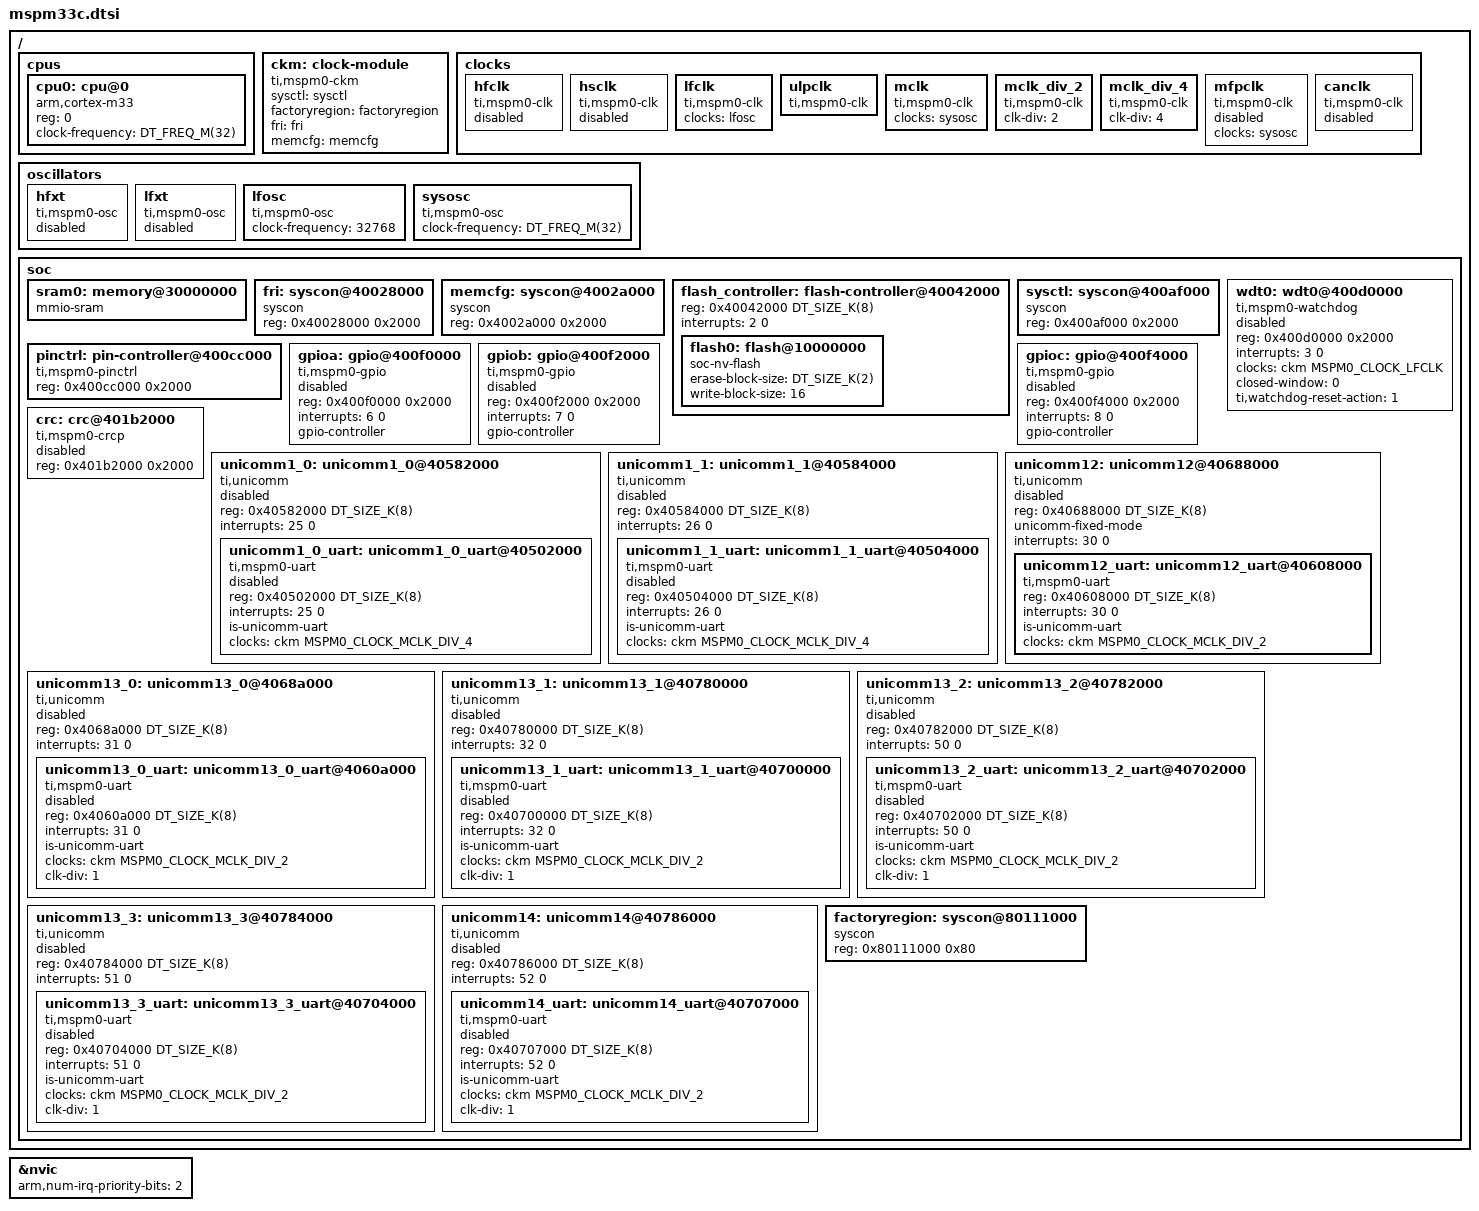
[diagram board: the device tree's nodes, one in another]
/*
 * Copyright (c) 2026 Texas Instruments
 * SPDX-License-Identifier: Apache-2.0
 */

#include <arm/armv8-m.dtsi>
#include <freq.h>
#include <zephyr/dt-bindings/clock/mspm0_clock.h>

/ {
	cpus {
		#address-cells = <1>;
		#size-cells = <0>;

		cpu0: cpu@0 {
			compatible = "arm,cortex-m33";
			reg = <0>;
			device_type = "cpu";
			clock-frequency = <DT_FREQ_M(32)>;
		};
	};

	ckm: clock-module {
		compatible = "ti,mspm0-ckm";
		#clock-cells = <1>;
		sysctl = <&sysctl>;
		factoryregion = <&factoryregion>;
		fri = <&fri>;
		memcfg = <&memcfg>;
	};

	clocks: clocks {
		hfclk: hfclk {
			compatible = "ti,mspm0-clk";
			#clock-cells = <0>;
			status = "disabled";
		};

		hsclk: hsclk {
			compatible = "ti,mspm0-clk";
			#clock-cells = <0>;
			status = "disabled";
		};

		lfclk: lfclk {
			compatible = "ti,mspm0-clk";
			#clock-cells = <0>;
			clocks = <&lfosc>;
		};

		ulpclk: ulpclk {
			compatible = "ti,mspm0-clk";
			#clock-cells = <0>;
		};

		mclk: mclk {
			compatible = "ti,mspm0-clk";
			#clock-cells = <0>;
			clocks = <&sysosc>;
		};

		mclk_div_2: mclk_div_2 {
			compatible = "ti,mspm0-clk";
			#clock-cells = <0>;
			clk-div = <2>;
		};

		mclk_div_4: mclk_div_4 {
			compatible = "ti,mspm0-clk";
			#clock-cells = <0>;
			clk-div = <4>;
		};

		mfpclk: mfpclk {
			compatible = "ti,mspm0-clk";
			#clock-cells = <0>;
			clocks = <&sysosc>;
			status = "disabled";
		};

		canclk: canclk {
			compatible = "ti,mspm0-clk";
			#clock-cells = <0>;
			status = "disabled";
		};
	};

	oscillators: oscillators {
		hfxt: hfxt {
			compatible = "ti,mspm0-osc";
			#clock-cells = <0>;
			status = "disabled";
		};

		lfxt: lfxt {
			compatible = "ti,mspm0-osc";
			#clock-cells = <0>;
			status = "disabled";
		};

		lfosc: lfosc {
			compatible = "ti,mspm0-osc";
			#clock-cells = <0>;
			clock-frequency = <32768>;
		};

		sysosc: sysosc {
			compatible = "ti,mspm0-osc";
			#clock-cells = <0>;
			clock-frequency = <DT_FREQ_M(32)>;
		};
	};

	soc {
		sram0: memory@30000000 {
			compatible = "mmio-sram";
		};

		fri: syscon@40028000 {
			compatible = "syscon";
			reg = <0x40028000 0x2000>;
		};

		memcfg: syscon@4002a000 {
			compatible = "syscon";
			reg = <0x4002a000 0x2000>;
		};

		flash_controller: flash-controller@40042000 {
			reg = <0x40042000 DT_SIZE_K(8)>;
			ranges;
			interrupts = <2 0>;
			#address-cells = <1>;
			#size-cells = <1>;

			flash0: flash@10000000 {
				compatible = "soc-nv-flash";
				erase-block-size = <DT_SIZE_K(2)>;
				write-block-size = <16>;
				#address-cells = <1>;
				#size-cells = <1>;
			};
		};

		sysctl: syscon@400af000 {
			compatible = "syscon";
			reg = <0x400af000 0x2000>;
			status = "okay";
		};

		pinctrl: pin-controller@400cc000 {
			compatible = "ti,mspm0-pinctrl";
			reg = <0x400cc000 0x2000>;
		};

		wdt0: wdt0@400d0000 {
			compatible = "ti,mspm0-watchdog";
			reg = <0x400d0000 0x2000>;
			interrupts = <3 0>;
			clocks = <&ckm MSPM0_CLOCK_LFCLK>;
			closed-window = <0>;
			ti,watchdog-reset-action = <1>;
			status = "disabled";
		};

		gpioa: gpio@400f0000 {
			compatible = "ti,mspm0-gpio";
			reg = <0x400f0000 0x2000>;
			interrupts = <6 0>;
			gpio-controller;
			#gpio-cells = <2>;
			status = "disabled";
		};

		gpiob: gpio@400f2000 {
			compatible = "ti,mspm0-gpio";
			reg = <0x400f2000 0x2000>;
			interrupts = <7 0>;
			gpio-controller;
			#gpio-cells = <2>;
			status = "disabled";
		};

		gpioc: gpio@400f4000 {
			compatible = "ti,mspm0-gpio";
			reg = <0x400f4000 0x2000>;
			interrupts = <8 0>;
			gpio-controller;
			#gpio-cells = <2>;
			status = "disabled";
		};

		crc: crc@401b2000 {
			compatible = "ti,mspm0-crcp";
			reg = <0x401b2000 0x2000>;
			status = "disabled";
		};

		unicomm1_0: unicomm1_0@40582000 {
			compatible = "ti,unicomm";
			reg = <0x40582000 DT_SIZE_K(8)>;
			interrupts = <25 0>;
			#address-cells = <1>;
			#size-cells = <1>;
			status = "disabled";

			unicomm1_0_uart: unicomm1_0_uart@40502000 {
				compatible = "ti,mspm0-uart";
				reg = <0x40502000 DT_SIZE_K(8)>;
				interrupts = <25 0>;
				#address-cells = <1>;
				#size-cells = <1>;
				is-unicomm-uart;
				clocks = <&ckm MSPM0_CLOCK_MCLK_DIV_4>;
				status = "disabled";
			};
		};

		unicomm1_1: unicomm1_1@40584000 {
			compatible = "ti,unicomm";
			reg = <0x40584000 DT_SIZE_K(8)>;
			interrupts = <26 0>;
			#address-cells = <1>;
			#size-cells = <1>;
			status = "disabled";

			unicomm1_1_uart: unicomm1_1_uart@40504000 {
				compatible = "ti,mspm0-uart";
				reg = <0x40504000 DT_SIZE_K(8)>;
				interrupts = <26 0>;
				#address-cells = <1>;
				#size-cells = <1>;
				is-unicomm-uart;
				clocks = <&ckm MSPM0_CLOCK_MCLK_DIV_4>;
				status = "disabled";
			};
		};

		unicomm12: unicomm12@40688000 {
			compatible = "ti,unicomm";
			reg = <0x40688000 DT_SIZE_K(8)>;
			unicomm-fixed-mode;
			interrupts = <30 0>;
			#address-cells = <1>;
			#size-cells = <1>;
			status = "disabled";

			unicomm12_uart: unicomm12_uart@40608000 {
				compatible = "ti,mspm0-uart";
				reg = <0x40608000 DT_SIZE_K(8)>;
				interrupts = <30 0>;
				#address-cells = <1>;
				#size-cells = <1>;
				is-unicomm-uart;
				clocks = <&ckm MSPM0_CLOCK_MCLK_DIV_2>;
			};
		};

		unicomm13_0: unicomm13_0@4068a000 {
			compatible = "ti,unicomm";
			reg = <0x4068a000 DT_SIZE_K(8)>;
			interrupts = <31 0>;
			#address-cells = <1>;
			#size-cells = <1>;
			status = "disabled";

			unicomm13_0_uart: unicomm13_0_uart@4060a000 {
				compatible = "ti,mspm0-uart";
				reg = <0x4060a000 DT_SIZE_K(8)>;
				interrupts = <31 0>;
				#address-cells = <1>;
				#size-cells = <1>;
				is-unicomm-uart;
				clocks = <&ckm MSPM0_CLOCK_MCLK_DIV_2>;
				clk-div = <1>;
				status = "disabled";
			};
		};

		unicomm13_1: unicomm13_1@40780000 {
			compatible = "ti,unicomm";
			reg = <0x40780000 DT_SIZE_K(8)>;
			interrupts = <32 0>;
			#address-cells = <1>;
			#size-cells = <1>;
			status = "disabled";

			unicomm13_1_uart: unicomm13_1_uart@40700000 {
				compatible = "ti,mspm0-uart";
				reg = <0x40700000 DT_SIZE_K(8)>;
				interrupts = <32 0>;
				#address-cells = <1>;
				#size-cells = <1>;
				is-unicomm-uart;
				clocks = <&ckm MSPM0_CLOCK_MCLK_DIV_2>;
				clk-div = <1>;
				status = "disabled";
			};
		};

		unicomm13_2: unicomm13_2@40782000 {
			compatible = "ti,unicomm";
			reg = <0x40782000 DT_SIZE_K(8)>;
			interrupts = <50 0>;
			#address-cells = <1>;
			#size-cells = <1>;
			status = "disabled";

			unicomm13_2_uart: unicomm13_2_uart@40702000 {
				compatible = "ti,mspm0-uart";
				reg = <0x40702000 DT_SIZE_K(8)>;
				interrupts = <50 0>;
				#address-cells = <1>;
				#size-cells = <1>;
				is-unicomm-uart;
				clocks = <&ckm MSPM0_CLOCK_MCLK_DIV_2>;
				clk-div = <1>;
				status = "disabled";
			};
		};

		unicomm13_3: unicomm13_3@40784000 {
			compatible = "ti,unicomm";
			reg = <0x40784000 DT_SIZE_K(8)>;
			interrupts = <51 0>;
			#address-cells = <1>;
			#size-cells = <1>;
			status = "disabled";

			unicomm13_3_uart: unicomm13_3_uart@40704000 {
				compatible = "ti,mspm0-uart";
				reg = <0x40704000 DT_SIZE_K(8)>;
				interrupts = <51 0>;
				#address-cells = <1>;
				#size-cells = <1>;
				is-unicomm-uart;
				clocks = <&ckm MSPM0_CLOCK_MCLK_DIV_2>;
				clk-div = <1>;
				status = "disabled";
			};
		};

		unicomm14: unicomm14@40786000 {
			compatible = "ti,unicomm";
			reg = <0x40786000 DT_SIZE_K(8)>;
			interrupts = <52 0>;
			#address-cells = <1>;
			#size-cells = <1>;
			status = "disabled";

			unicomm14_uart: unicomm14_uart@40707000 {
				compatible = "ti,mspm0-uart";
				reg = <0x40707000 DT_SIZE_K(8)>;
				interrupts = <52 0>;
				#address-cells = <1>;
				#size-cells = <1>;
				is-unicomm-uart;
				clocks = <&ckm MSPM0_CLOCK_MCLK_DIV_2>;
				clk-div = <1>;
				status = "disabled";
			};
		};

		factoryregion: syscon@80111000 {
			compatible = "syscon";
			reg = <0x80111000 0x80>;
		};
	};
};

&nvic {
	arm,num-irq-priority-bits = <2>;
};
